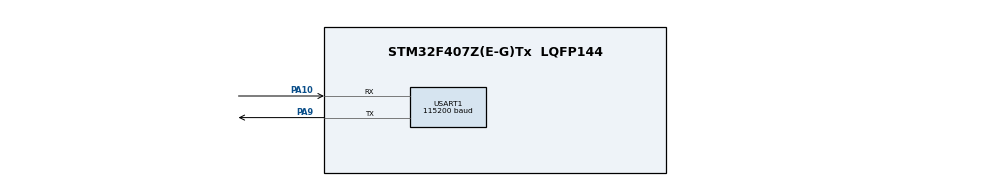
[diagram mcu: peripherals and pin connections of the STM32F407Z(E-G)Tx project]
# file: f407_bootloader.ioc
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Mcu.Family=STM32F4
Mcu.Name=STM32F407Z(E-G)Tx
Mcu.Package=LQFP144
PA9.Mode=Asynchronous
PA9.Signal=USART1_TX
PA10.Mode=Asynchronous
PA10.Signal=USART1_RX
ProjectManager.StackSize=0x400
ProjectManager.TargetToolchain=STM32CubeIDE
RCC.HSEState=HSE_ON
RCC.PLLM=8
RCC.PLLN=336
RCC.PLLP=2
RCC.PLLQ=7
RCC.SYSCLKSource=RCC_SYSCLKSOURCE_PLLCLK
USART1.BaudRate=115200
USART1.Mode=Asynchronous
USART1.Parity=None
USART1.StopBits=1
USART1.WordLength=8b

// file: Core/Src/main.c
/* USER CODE BEGIN Header */
/**
  ******************************************************************************
  * @file           : main.c
  * @brief          : F407 Bootloader 最小工程（USART1 115200 打印 BOOT v0.1）
  *                   工程：firmware/bootloader，代码占 Sector 0-2（48KB），Sector 3 为 APP 元数据
  ******************************************************************************
  */
/* USER CODE END Header */
#include "main.h"
#include "usart.h"
#include "bl_uart.h"
#include "bl_protocol.h"
#include "bl_flash.h"

/* USER CODE BEGIN Includes */
#include <stdio.h>
/* USER CODE END Includes */

void SystemClock_Config(void);

int main(void)
{
  /* MCU Configuration--------------------------------------------------------*/
  /* Reset of all peripherals, Initializes the Flash interface and the Systick. */
  HAL_Init();

  /* Configure the system clock */
  SystemClock_Config();

  /* Initialize all configured peripherals */
  MX_USART1_UART_Init();

  /* USER CODE BEGIN 2 */
  printf("BOOT v0.1\r\n");

  /* 1s 握手窗口：u=升级模式，j=强制跳转（调试），超时=默认路径 */
  uint8_t ch = 0;
  int got = 0;
  for (uint32_t i = 0; i < 1000; i++)
  {
    if (UART_GetByte(&ch)) { got = 1; break; }
    HAL_Delay(1);
  }

  if (got && ch == 'u')
  {
    printf("UPGRADE MODE\r\n");
    BlProtocolRun();                 /* 不返回 */
  }
  else if (got && ch == 'j')
  {
    BlJumpToApp();                    /* 强制跳转（调试用，不检查 magic） */
  }
  else
  {
    if (BlAppValid())
    {
      BlJumpToApp();
    }
    printf("NO APP\r\n");
    while (1) { HAL_Delay(1000); }
  }
  /* USER CODE END 2 */
}

void SystemClock_Config(void)
{
  RCC_OscInitTypeDef RCC_OscInitStruct = {0};
  RCC_ClkInitTypeDef RCC_ClkInitStruct = {0};

  /** Configure the main internal regulator output voltage
  */
  __HAL_RCC_PWR_CLK_ENABLE();
  __HAL_PWR_VOLTAGESCALING_CONFIG(PWR_REGULATOR_VOLTAGE_SCALE1);

  /** Initializes the RCC Oscillators according to the specified parameters
  * in the RCC_OscInitTypeDef structure.
  */
  RCC_OscInitStruct.OscillatorType = RCC_OSCILLATORTYPE_HSE;
  RCC_OscInitStruct.HSEState = RCC_HSE_ON;
  RCC_OscInitStruct.PLL.PLLState = RCC_PLL_ON;
  RCC_OscInitStruct.PLL.PLLSource = RCC_PLLSOURCE_HSE;
  RCC_OscInitStruct.PLL.PLLM = 8;
  RCC_OscInitStruct.PLL.PLLN = 336;
  RCC_OscInitStruct.PLL.PLLP = RCC_PLLP_DIV2;
  RCC_OscInitStruct.PLL.PLLQ = 7;
  if (HAL_RCC_OscConfig(&RCC_OscInitStruct) != HAL_OK)
  {
    Error_Handler();
  }

  /** Initializes the CPU, AHB and APB buses clocks
  */
  RCC_ClkInitStruct.ClockType = RCC_CLOCKTYPE_HCLK|RCC_CLOCKTYPE_SYSCLK
                              |RCC_CLOCKTYPE_PCLK1|RCC_CLOCKTYPE_PCLK2;
  RCC_ClkInitStruct.SYSCLKSource = RCC_SYSCLKSOURCE_PLLCLK;
  RCC_ClkInitStruct.AHBCLKDivider = RCC_SYSCLK_DIV1;
  RCC_ClkInitStruct.APB1CLKDivider = RCC_HCLK_DIV4;
  RCC_ClkInitStruct.APB2CLKDivider = RCC_HCLK_DIV2;

  if (HAL_RCC_ClockConfig(&RCC_ClkInitStruct, FLASH_LATENCY_5) != HAL_OK)
  {
    Error_Handler();
  }
}

void Error_Handler(void)
{
  __disable_irq();
  while (1)
  {
  }
}
